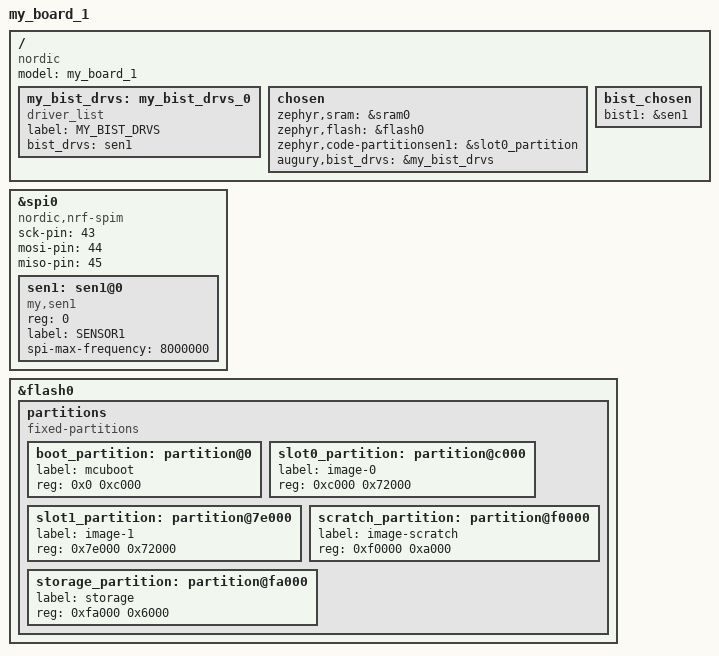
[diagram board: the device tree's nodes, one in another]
// Copyright (c) 2022 Nordic Semiconductor ASA
// SPDX-License-Identifier: Apache-2.0

/dts-v1/;
#include <nordic/nrf52840_qiaa.dtsi>

/ {
	model = "my_board_1";
	compatible = "nordic";

	my_bist_drvs: my_bist_drvs_0 {
		status = "okay";
		compatible = "driver_list";
		label = "MY_BIST_DRVS";
		bist_drvs = <&sen1>;
	};

	chosen {
		zephyr,sram = &sram0;
		zephyr,flash = &flash0;
		zephyr,code-partitionsen1 = &slot0_partition;	
		augury,bist_drvs = &my_bist_drvs;
	};

	bist_chosen {
		bist1 = &sen1;
	};
	
	// aliases {
	// 	drv_list = &my_bist_drvs_0;
	// };

	
};


&spi0 {
	compatible = "nordic,nrf-spim";
	status = "okay";
	sck-pin = <43>;
	mosi-pin = <44>;
	miso-pin = <45>;
	// cs-gpios = <&gpio1 10 GPIO_ACTIVE_LOW>;
	sen1: sen1@0 {
		compatible = "my,sen1";
		reg = <0>;
		label = "SENSOR1";
		spi-max-frequency = <8000000>;
	};
};

// &spi1 {
// 	status = "okay";
// 	sck-pin = <3>;
// 	mosi-pin = <2>;
// 	miso-pin = <29>;
// 	compatible = "nordic,nrf-spim";
// 	cs-gpios = <&gpio1 4 GPIO_ACTIVE_LOW>;
// 	sen2@0 {
// 		compatible = "my,sen2";
// 		reg = <0>;
// 		irq_gpios = <&gpio0 26 (GPIO_ACTIVE_HIGH | GPIO_PULL_DOWN)>;
// 		label = "SENSOR2";
// 		spi-max-frequency = <8000000>;
// 	};
// };


&flash0 {
	partitions {
		compatible = "fixed-partitions";
		#address-cells = <1>;
		#size-cells = <1>;

		boot_partition: partition@0 {
			label = "mcuboot";
			reg = <0x0 0xc000>;
		};
		slot0_partition: partition@c000 {
			label = "image-0";
			reg = <0xc000 0x72000>;
		};
		slot1_partition: partition@7e000 {
			label = "image-1";
			reg = <0x7e000 0x72000>;
		};
		scratch_partition: partition@f0000 {
			label = "image-scratch";
			reg = <0xf0000 0xa000>;
		};
		storage_partition: partition@fa000 {
			label = "storage";
			reg = <0xfa000 0x6000>;
		};
	};
};

